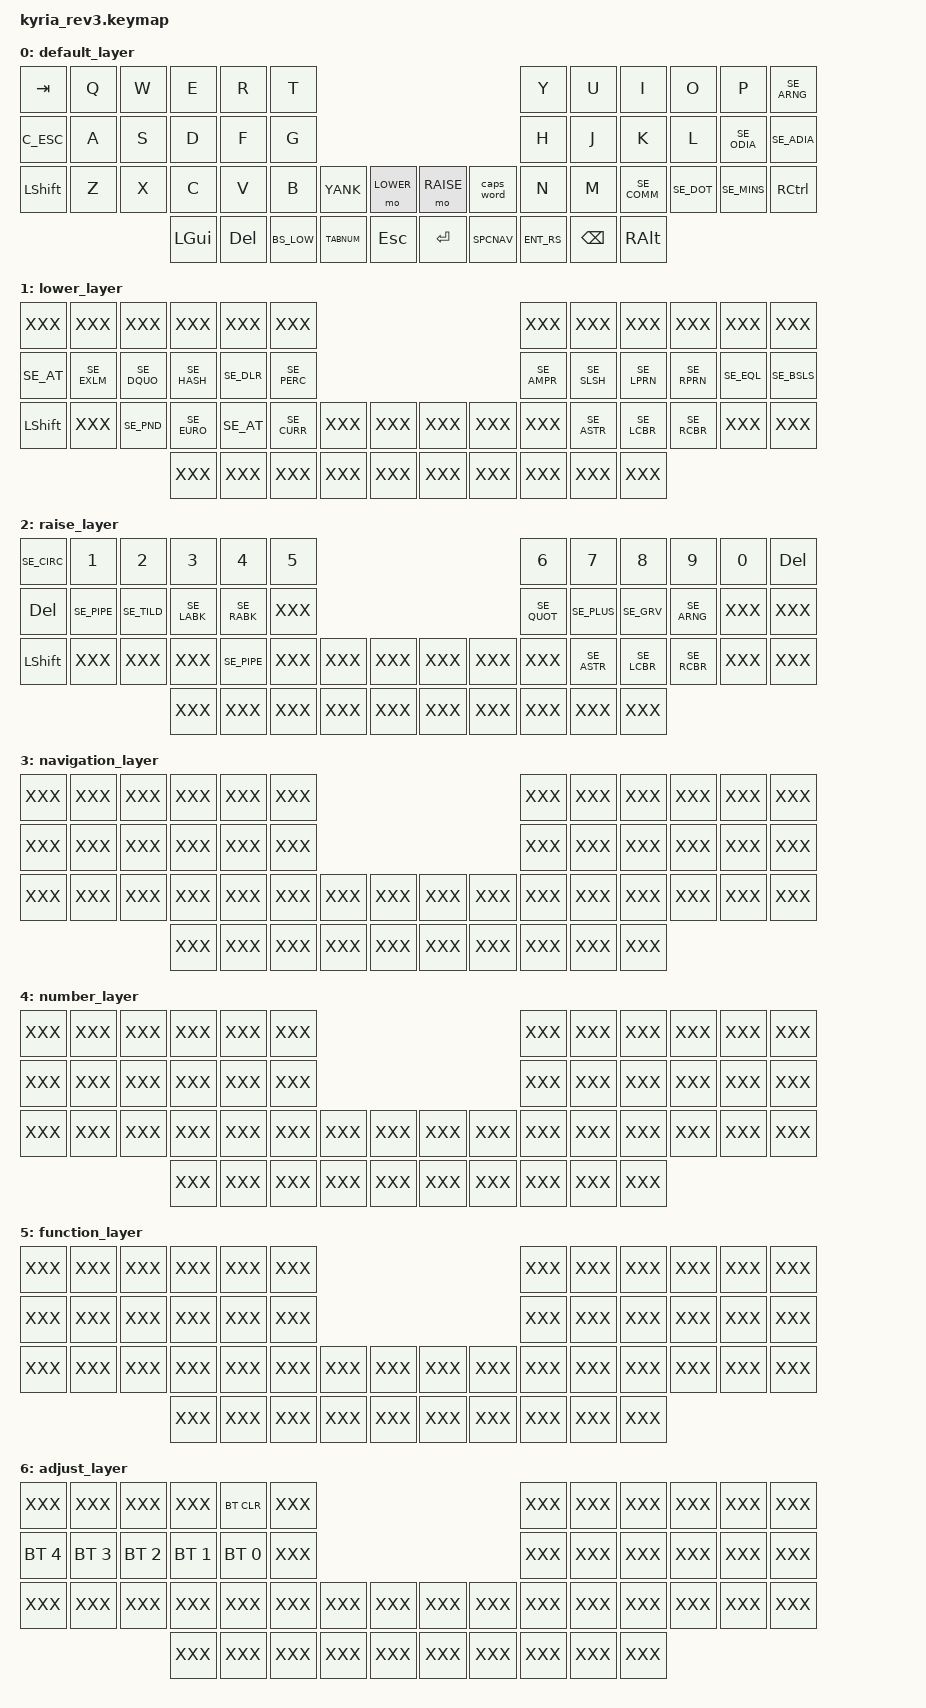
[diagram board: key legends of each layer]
/*
 * Copyright (c) 2023 takikoo
 *
 * SPDX-License-Identifier: MIT
 */

#include <behaviors.dtsi>
#include <dt-bindings/zmk/bt.h>
#include <dt-bindings/zmk/keys.h>

#include <swedish.h>
#include <yonyon.h>
#include "macros.dtsi"

// &left_encoder { resolution = <2>; };
// &right_encoder { resolution = <2>; };
&caps_word { continue-list = <SE_UNDS SE_MINS BACKSPACE>; };

/ {
    conditional_layers {
        compatible = "zmk,conditional-layers";
        tri_layer {
            if-layers = <LOWER RAISE>;
            then-layer = <ADJUST>;
        };
    };
};

/ {
    keymap {
        compatible = "zmk,keymap";

        default_layer {
            bindings = <
            // clang-format off
//╭─────────────┬─────────────┬─────────────┬─────────────┬─────────────┬─────────────╮                                                          ╭─────────────┬─────────────┬─────────────┬─────────────┬─────────────┬─────────────╮
    &kp TAB       &kp Q         &kp W         &kp E         &kp R         &kp T                                                                    &kp Y         &kp U         &kp I         &kp O         &kp P         &kp SE_ARNG
//├─────────────┼─────────────┼─────────────┼─────────────┼─────────────┼─────────────┤                                                          ├─────────────┼─────────────┼─────────────┼─────────────┼─────────────┼─────────────┤
    C_ESC         &kp A         &kp S         &kp D         &kp F         &kp G                                                                    &kp H         &kp J         &kp K         &kp L         &kp SE_ODIA   &kp SE_ADIA
//├─────────────┼─────────────┼─────────────┼─────────────┼─────────────┼─────────────┼─────────────┬─────────────╮  ╭─────────────┬─────────────┼─────────────┼─────────────┼─────────────┼─────────────┼─────────────┼─────────────┤
    &kp LSHFT     &kp Z         &kp X         &kp C         &kp V         &kp B         YANK          &mo LOWER        &mo RAISE     &caps_word    &kp N         &kp M         &kp SE_COMM   &kp SE_DOT    &kp SE_MINS   &kp RCTRL
//╰─────────────┴─────────────┴─────────────┼─────────────┼─────────────┼─────────────┼─────────────┼─────────────┤  ├─────────────┼─────────────┼─────────────┼─────────────┴─────────────┼─────────────┴─────────────┴─────────────╯
                                              &kp LGUI      &kp DEL       BS_LOW        TABNUM        &kp ESC          &kp RET       SPCNAV        ENT_RS        &kp BSPC      &kp RALT
//                                          ╰─────────────┴─────────────┴─────────────┴─────────────┴─────────────╯  ╰─────────────┴─────────────┴─────────────┴─────────────┴─────────────╯
            // clang-format on
            >;
            sensor-bindings = <
              &inc_dec_kp TAB_NEXT TAB_PREV
              &inc_dec_kp PG_UP    PG_DN
            >;
        };

        lower_layer {
            bindings = <
            // clang-format off
//╭─────────────┬─────────────┬─────────────┬─────────────┬─────────────┬─────────────╮                                                          ╭─────────────┬─────────────┬─────────────┬─────────────┬─────────────┬─────────────╮
    XXX           XXX           XXX           XXX           XXX           XXX                                                                      XXX           XXX           XXX           XXX           XXX           XXX
//├─────────────┼─────────────┼─────────────┼─────────────┼─────────────┼─────────────┤                                                          ├─────────────┼─────────────┼─────────────┼─────────────┼─────────────┼─────────────┤
    &kp SE_AT     &kp SE_EXLM   &kp SE_DQUO   &kp SE_HASH   &kp SE_DLR    &kp SE_PERC                                                              &kp SE_AMPR   &kp SE_SLSH   &kp SE_LPRN   &kp SE_RPRN   &kp SE_EQL    &kp SE_BSLS
//├─────────────┼─────────────┼─────────────┼─────────────┼─────────────┼─────────────┼─────────────┬─────────────╮  ╭─────────────┬─────────────┼─────────────┼─────────────┼─────────────┼─────────────┼─────────────┼─────────────┤
    &kp LSHFT     XXX           &kp SE_PND    &kp SE_EURO   &kp SE_AT     &kp SE_CURR   XXX           XXX              XXX           XXX           XXX           &kp SE_ASTR   &kp SE_LCBR   &kp SE_RCBR   XXX           XXX
//╰─────────────┴─────────────┴─────────────┼─────────────┼─────────────┼─────────────┼─────────────┼─────────────┤  ├─────────────┼─────────────┼─────────────┼─────────────┴─────────────┼─────────────┴─────────────┴─────────────╯
                                              XXX           XXX           XXX           XXX           XXX              XXX           XXX           XXX           XXX           XXX
//                                          ╰─────────────┴─────────────┴─────────────┴─────────────┴─────────────╯  ╰─────────────┴─────────────┴─────────────┴─────────────┴─────────────╯
            // clang-format on
            >;
            sensor-bindings = <
              &inc_dec_kp C_VOL_UP C_VOL_DN
              &inc_dec_kp PG_UP    PG_DN
            >;
        };

        raise_layer {
            bindings = <
            // clang-format off
//╭─────────────┬─────────────┬─────────────┬─────────────┬─────────────┬─────────────╮                                                          ╭─────────────┬─────────────┬─────────────┬─────────────┬─────────────┬─────────────╮
    &kp SE_CIRC   &kp N1        &kp N2        &kp N3        &kp N4        &kp N5                                                                   &kp N6        &kp N7        &kp N8        &kp N9        &kp N0        &kp DEL
//├─────────────┼─────────────┼─────────────┼─────────────┼─────────────┼─────────────┤                                                          ├─────────────┼─────────────┼─────────────┼─────────────┼─────────────┼─────────────┤
    &kp DEL       &kp SE_PIPE   &kp SE_TILD   &kp SE_LABK   &kp SE_RABK   XXX                                                                      &kp SE_QUOT   &kp SE_PLUS   &kp SE_GRV    &kp SE_ARNG   XXX           XXX
//├─────────────┼─────────────┼─────────────┼─────────────┼─────────────┼─────────────┼─────────────┬─────────────╮  ╭─────────────┬─────────────┼─────────────┼─────────────┼─────────────┼─────────────┼─────────────┼─────────────┤
    &kp LSHFT     XXX           XXX           XXX           &kp SE_PIPE   XXX           XXX           XXX              XXX           XXX           XXX           &kp SE_ASTR   &kp SE_LCBR   &kp SE_RCBR   XXX           XXX
//╰─────────────┴─────────────┴─────────────┼─────────────┼─────────────┼─────────────┼─────────────┼─────────────┤  ├─────────────┼─────────────┼─────────────┼─────────────┴─────────────┼─────────────┴─────────────┴─────────────╯
                                              XXX           XXX           XXX           XXX           XXX              XXX           XXX           XXX           XXX           XXX
//                                          ╰─────────────┴─────────────┴─────────────┴─────────────┴─────────────╯  ╰─────────────┴─────────────┴─────────────┴─────────────┴─────────────╯
            // clang-format on
            >;
            sensor-bindings = <
              &inc_dec_kp C_VOL_UP C_VOL_DN
              &inc_dec_kp PG_UP    PG_DN
            >;

        };

        navigation_layer {
            bindings = <
            // clang-format off
//╭─────────────┬─────────────┬─────────────┬─────────────┬─────────────┬─────────────╮                                                          ╭─────────────┬─────────────┬─────────────┬─────────────┬─────────────┬─────────────╮
    XXX           XXX           XXX           XXX           XXX           XXX                                                                      XXX           XXX           XXX           XXX           XXX           XXX
//├─────────────┼─────────────┼─────────────┼─────────────┼─────────────┼─────────────┤                                                          ├─────────────┼─────────────┼─────────────┼─────────────┼─────────────┼─────────────┤
    XXX           XXX           XXX           XXX           XXX           XXX                                                                      XXX           XXX           XXX           XXX           XXX           XXX
//├─────────────┼─────────────┼─────────────┼─────────────┼─────────────┼─────────────┼─────────────┬─────────────╮  ╭─────────────┬─────────────┼─────────────┼─────────────┼─────────────┼─────────────┼─────────────┼─────────────┤
    XXX           XXX           XXX           XXX           XXX           XXX           XXX           XXX              XXX           XXX           XXX           XXX           XXX           XXX           XXX           XXX
//╰─────────────┴─────────────┴─────────────┼─────────────┼─────────────┼─────────────┼─────────────┼─────────────┤  ├─────────────┼─────────────┼─────────────┼─────────────┴─────────────┼─────────────┴─────────────┴─────────────╯
                                              XXX           XXX           XXX           XXX           XXX              XXX           XXX           XXX           XXX           XXX
//                                          ╰─────────────┴─────────────┴─────────────┴─────────────┴─────────────╯  ╰─────────────┴─────────────┴─────────────┴─────────────┴─────────────╯
            // clang-format on
            >;
            sensor-bindings = <
              &inc_dec_kp C_VOL_UP C_VOL_DN
              &inc_dec_kp PG_UP    PG_DN
            >;
        };

        number_layer {
            bindings = <
            // clang-format off
//╭─────────────┬─────────────┬─────────────┬─────────────┬─────────────┬─────────────╮                                                          ╭─────────────┬─────────────┬─────────────┬─────────────┬─────────────┬─────────────╮
    XXX           XXX           XXX           XXX           XXX           XXX                                                                      XXX           XXX           XXX           XXX           XXX           XXX
//├─────────────┼─────────────┼─────────────┼─────────────┼─────────────┼─────────────┤                                                          ├─────────────┼─────────────┼─────────────┼─────────────┼─────────────┼─────────────┤
    XXX           XXX           XXX           XXX           XXX           XXX                                                                      XXX           XXX           XXX           XXX           XXX           XXX
//├─────────────┼─────────────┼─────────────┼─────────────┼─────────────┼─────────────┼─────────────┬─────────────╮  ╭─────────────┬─────────────┼─────────────┼─────────────┼─────────────┼─────────────┼─────────────┼─────────────┤
    XXX           XXX           XXX           XXX           XXX           XXX           XXX           XXX              XXX           XXX           XXX           XXX           XXX           XXX           XXX           XXX
//╰─────────────┴─────────────┴─────────────┼─────────────┼─────────────┼─────────────┼─────────────┼─────────────┤  ├─────────────┼─────────────┼─────────────┼─────────────┴─────────────┼─────────────┴─────────────┴─────────────╯
                                              XXX           XXX           XXX           XXX           XXX              XXX           XXX           XXX           XXX           XXX
//                                          ╰─────────────┴─────────────┴─────────────┴─────────────┴─────────────╯  ╰─────────────┴─────────────┴─────────────┴─────────────┴─────────────╯
            // clang-format on
            >;
            sensor-bindings = <
              &inc_dec_kp C_VOL_UP C_VOL_DN
              &inc_dec_kp PG_UP    PG_DN
            >;
        };

        function_layer {
            bindings = <
            // clang-format off
//╭─────────────┬─────────────┬─────────────┬─────────────┬─────────────┬─────────────╮                                                          ╭─────────────┬─────────────┬─────────────┬─────────────┬─────────────┬─────────────╮
    XXX           XXX           XXX           XXX           XXX           XXX                                                                      XXX           XXX           XXX           XXX           XXX           XXX
//├─────────────┼─────────────┼─────────────┼─────────────┼─────────────┼─────────────┤                                                          ├─────────────┼─────────────┼─────────────┼─────────────┼─────────────┼─────────────┤
    XXX           XXX           XXX           XXX           XXX           XXX                                                                      XXX           XXX           XXX           XXX           XXX           XXX
//├─────────────┼─────────────┼─────────────┼─────────────┼─────────────┼─────────────┼─────────────┬─────────────╮  ╭─────────────┬─────────────┼─────────────┼─────────────┼─────────────┼─────────────┼─────────────┼─────────────┤
    XXX           XXX           XXX           XXX           XXX           XXX           XXX           XXX              XXX           XXX           XXX           XXX           XXX           XXX           XXX           XXX
//╰─────────────┴─────────────┴─────────────┼─────────────┼─────────────┼─────────────┼─────────────┼─────────────┤  ├─────────────┼─────────────┼─────────────┼─────────────┴─────────────┼─────────────┴─────────────┴─────────────╯
                                              XXX           XXX           XXX           XXX           XXX              XXX           XXX           XXX           XXX           XXX
//                                          ╰─────────────┴─────────────┴─────────────┴─────────────┴─────────────╯  ╰─────────────┴─────────────┴─────────────┴─────────────┴─────────────╯
            // clang-format on
            >;
            sensor-bindings = <
              &inc_dec_kp C_VOL_UP C_VOL_DN
              &inc_dec_kp PG_UP    PG_DN
            >;
        };

//         empty_layer {
//             bindings = <
//             // clang-format off
// //╭─────────────┬─────────────┬─────────────┬─────────────┬─────────────┬─────────────╮                                                          ╭─────────────┬─────────────┬─────────────┬─────────────┬─────────────┬─────────────╮
//     XXX           XXX           XXX           XXX           XXX           XXX                                                                      XXX           XXX           XXX           XXX           XXX           XXX
// //├─────────────┼─────────────┼─────────────┼─────────────┼─────────────┼─────────────┤                                                          ├─────────────┼─────────────┼─────────────┼─────────────┼─────────────┼─────────────┤
//     XXX           XXX           XXX           XXX           XXX           XXX                                                                      XXX           XXX           XXX           XXX           XXX           XXX
// //├─────────────┼─────────────┼─────────────┼─────────────┼─────────────┼─────────────┼─────────────┬─────────────╮  ╭─────────────┬─────────────┼─────────────┼─────────────┼─────────────┼─────────────┼─────────────┼─────────────┤
//     XXX           XXX           XXX           XXX           XXX           XXX           XXX           XXX              XXX           XXX           XXX           XXX           XXX           XXX           XXX           XXX
// //╰─────────────┴─────────────┴─────────────┼─────────────┼─────────────┼─────────────┼─────────────┼─────────────┤  ├─────────────┼─────────────┼─────────────┼─────────────┴─────────────┼─────────────┴─────────────┴─────────────╯
//                                               XXX           XXX           XXX           XXX           XXX              XXX           XXX           XXX           XXX           XXX
// //                                          ╰─────────────┴─────────────┴─────────────┴─────────────┴─────────────╯  ╰─────────────┴─────────────┴─────────────┴─────────────┴─────────────╯
//             // clang-format on
//             >;
//             sensor-bindings = <
//               &inc_dec_kp C_VOL_UP C_VOL_DN
//               &inc_dec_kp PG_UP    PG_DN
//             >;
//         };

        adjust_layer {
            bindings = <
            // clang-format off
//╭─────────────┬─────────────┬─────────────┬─────────────┬─────────────┬─────────────╮                                                          ╭─────────────┬─────────────┬─────────────┬─────────────┬─────────────┬─────────────╮
    XXX           XXX           XXX           XXX           &bt BT_CLR    XXX                                                                      XXX           XXX           XXX           XXX           XXX           XXX
//├─────────────┼─────────────┼─────────────┼─────────────┼─────────────┼─────────────┤                                                          ├─────────────┼─────────────┼─────────────┼─────────────┼─────────────┼─────────────┤
    &bt BT_SEL 4  &bt BT_SEL 3  &bt BT_SEL 2  &bt BT_SEL 1  &bt BT_SEL 0  XXX                                                                      XXX           XXX           XXX           XXX           XXX           XXX
//├─────────────┼─────────────┼─────────────┼─────────────┼─────────────┼─────────────┼─────────────┬─────────────╮  ╭─────────────┬─────────────┼─────────────┼─────────────┼─────────────┼─────────────┼─────────────┼─────────────┤
    XXX           XXX           XXX           XXX           XXX           XXX           XXX           XXX              XXX           XXX           XXX           XXX           XXX           XXX           XXX           XXX
//╰─────────────┴─────────────┴─────────────┼─────────────┼─────────────┼─────────────┼─────────────┼─────────────┤  ├─────────────┼─────────────┼─────────────┼─────────────┴─────────────┼─────────────┴─────────────┴─────────────╯
                                              XXX           XXX           XXX           XXX           XXX              XXX           XXX           XXX           XXX           XXX
//                                          ╰─────────────┴─────────────┴─────────────┴─────────────┴─────────────╯  ╰─────────────┴─────────────┴─────────────┴─────────────┴─────────────╯
            // clang-format on
            >;
            sensor-bindings = <
              &inc_dec_kp C_VOL_UP C_VOL_DN
              &inc_dec_kp PG_UP    PG_DN
            >;
        };

    };
};
